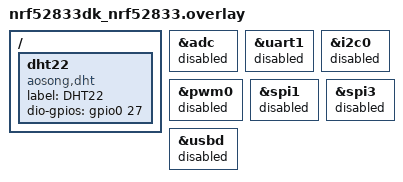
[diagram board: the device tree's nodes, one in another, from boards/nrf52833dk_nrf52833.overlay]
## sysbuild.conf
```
#
# Copyright (c) 2025 Nordic Semiconductor
#
# SPDX-License-Identifier: LicenseRef-Nordic-5-Clause
#

SB_CONFIG_MATTER=y

SB_CONFIG_MATTER_FACTORY_DATA_GENERATE=y
SB_CONFIG_MATTER_FACTORY_DATA_MERGE_WITH_FIRMWARE=y
```

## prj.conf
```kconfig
#
# Copyright (c) 2025 Nordic Semiconductor ASA
#
# SPDX-License-Identifier: LicenseRef-Nordic-5-Clause
#

#CONFIG_CHIP_DEVICE_ENABLE_KEY="10112233445566778899AABBCCDDEEFF"
#CONFIG_CHIP_DEVICE_SERIAL_NUMBER="10112233445566778899FAFBFCFDFEFA"
CONFIG_CHIP_DEVICE_DISCRIMINATOR=1113
CONFIG_CHIP_FACTORY_DATA_USE_DEFAULT_CERTS=n
CONFIG_CHIP_FACTORY_DATA_MERGE_WITH_FIRMWARE=y
CONFIG_CHIP_DEVICE_SPAKE2_PASSCODE=20202023
CONFIG_CHIP_DEVICE_SERIAL_NUMBER="12123434565678789093"

# Enable CHIP
CONFIG_CHIP=y
CONFIG_CHIP_ROTATING_DEVICE_ID=y
CONFIG_CHIP_DEVICE_GENERATE_ROTATING_DEVICE_UID=y
CONFIG_CHIP_PROJECT_CONFIG="src/chip_project_config.h"
CONFIG_CHIP_DEVICE_PRODUCT_NAME="Stube Temperatur Sensor"
CONFIG_BT_DEVICE_NAME="SchlafzimmerTemp"

# Configure ZAP file name
CONFIG_NCS_SAMPLE_MATTER_ZAP_FILE_PATH="${APPLICATION_CONFIG_DIR}/src/default_zap/temperature_sensor.zap"

# Based on https://github.com/project-chip/connectedhomeip/blob/482e6fd03196a6de45465a90003947ef4b86e0b1/docs/examples/discussion/PID_allocation_for_example_apps.md)
CONFIG_CHIP_DEVICE_PRODUCT_ID=32781
CONFIG_STD_CPP17=y

# Enable Matter pairing automatically on application start.
CONFIG_CHIP_ENABLE_PAIRING_AUTOSTART=y

# Enable Matter extended announcement and increase duration to 1 hour.
CONFIG_CHIP_BLE_EXT_ADVERTISING=y
CONFIG_CHIP_BLE_ADVERTISING_DURATION=60

# Add support for LEDs and buttons on Nordic development kits
CONFIG_DK_LIBRARY=y
CONFIG_NCS_SAMPLE_MATTER_LEDS=n

# Try to disable unused RAM blocks to reduce power consumption
CONFIG_RAM_POWER_DOWN_LIBRARY=n

# Bluetooth Low Energy configuration
CONFIG_BT_DEVICE_NAME="MatterTemperature"
CONFIG_BT_DEVICE_NAME_MAX=18

# Suspend devices when the CPU goes into sleep
CONFIG_PM_DEVICE=n
CONFIG_PM=n

# Enable system reset on fatal error
CONFIG_RESET_ON_FATAL_ERROR=y

# Disable all debug features
CONFIG_USE_SEGGER_RTT=n
CONFIG_SHELL=y
CONFIG_OPENTHREAD_SHELL=y
CONFIG_CONSOLE=y
CONFIG_UART_CONSOLE=y
CONFIG_SERIAL=y
CONFIG_LOG=y
CONFIG_LOG_MODE_MINIMAL=n
CONFIG_ASSERT_VERBOSE=n
CONFIG_ASSERT_NO_FILE_INFO=y
CONFIG_PRINTK=y
CONFIG_PRINTK_SYNC=n
CONFIG_THREAD_NAME=n
CONFIG_BOOT_BANNER=y

CONFIG_MCUMGR_TRANSPORT_UART=y

# Enable Factory Data feature
CONFIG_CHIP_FACTORY_DATA=y
CONFIG_CHIP_FACTORY_DATA_BUILD=y

# Enable Watchdog
CONFIG_NCS_SAMPLE_MATTER_WATCHDOG=y

# Enable LTO to decrease the flash usage.
CONFIG_LTO=y
CONFIG_ISR_TABLES_LOCAL_DECLARATION=y

CONFIG_NRFX_TEMP=n

CONFIG_SENSOR=y
CONFIG_DHT=y
CONFIG_DHT_LOCK_IRQS=y

CONFIG_SENSOR=y
CONFIG_TEMP_NRF5=y
```

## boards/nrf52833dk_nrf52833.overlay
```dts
/*
 * Copyright (c) 2025 Nordic Semiconductor ASA
 *
 * SPDX-License-Identifier: LicenseRef-Nordic-5-Clause
 */

/// {
//	chosen {
//		nordic,pm-ext-flash = &mx25r64;
//	};
//};

/* Disable unused peripherals to reduce power consumption */
&adc {
	status = "disabled";
};

&uart1 {
	status = "disabled";
};

&i2c0 {
	status = "disabled";
};

&pwm0 {
	status = "disabled";
};

&spi1 {
	status = "disabled";
};

&spi3 {
	status = "disabled";
};

&usbd {
	status = "disabled";
};

/ {
    dht22: dht22 {
        compatible = "aosong,dht";
        label = "DHT22";
        dio-gpios = <&gpio0 27 (GPIO_ACTIVE_HIGH)>;
    };
};
```

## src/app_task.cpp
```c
/*
 * Copyright (c) 2025 Nordic Semiconductor ASA
 *
 * SPDX-License-Identifier: LicenseRef-Nordic-5-Clause
 */

#include "app_task.h"

#include "app/matter_init.h"
#include "app/task_executor.h"
#include "board/board.h"
#include "clusters/identify.h"
#include "lib/core/CHIPError.h"
#include <drivers/include/nrfx_temp.h>

#include <app-common/zap-generated/attributes/Accessors.h>

#include <zephyr/logging/log.h>

#include <zephyr/device.h>
#include <zephyr/drivers/sensor.h>

const struct device *dht = DEVICE_DT_GET_ANY(aosong_dht);

#ifdef CONFIG_BME680
#include <zephyr/drivers/sensor.h>

const device *sBme688SensorDev = DEVICE_DT_GET_ONE(bosch_bme680);
#endif

LOG_MODULE_DECLARE(app, CONFIG_CHIP_APP_LOG_LEVEL);

using namespace ::chip;
using namespace ::chip::app;
using namespace ::chip::DeviceLayer;

namespace
{
constexpr chip::EndpointId kTemperatureSensorEndpointId = 1;

Nrf::Matter::IdentifyCluster sIdentifyCluster(kTemperatureSensorEndpointId);

#ifdef CONFIG_CHIP_ICD_UAT_SUPPORT
#ifdef CONFIG_NCS_SAMPLE_MATTER_USE_DEFAULT_BUTTON_HANDLER
#define UAT_BUTTON_MASK DK_BTN3_MSK
#endif
#endif

#ifndef CONFIG_NCS_SAMPLE_MATTER_USE_DEFAULT_BUTTON_HANDLER
constexpr int kSoftwareUpdateTimeout = 1500;
constexpr int kUatTimeout = 1500;
constexpr int kFactoryResetTimeout = 3000;
constexpr int kUatBlinkPeriod = 200;
ButtonState sBtnState = ButtonState::None;
k_timer sBtn1Timer;
#endif

} /* namespace */

void HandleUAT()
{
#ifdef CONFIG_CHIP_ICD_UAT_SUPPORT
	LOG_INF("ICD UserActiveMode has been triggered.");
	Server::GetInstance().GetICDManager().OnNetworkActivity();
#endif
}
/* nRF54T15 TAG has only a single button,
 * therefore the default handler for factory data and software update had to be overriden.
 * On other DK's only UAT is handled by the application.
 */
void AppTask::ButtonEventHandler(Nrf::ButtonState state, Nrf::ButtonMask hasChanged)
{
#ifdef CONFIG_NCS_SAMPLE_MATTER_USE_DEFAULT_BUTTON_HANDLER
	if (UAT_BUTTON_MASK & state & hasChanged) {
		HandleUAT();
	}
#else
	if (DK_BTN1_MSK & hasChanged) {
		if (DK_BTN1_MSK & state) {
			LOG_INF("Release the button within %ums to trigger Software Update", kSoftwareUpdateTimeout);
			k_timer_start(&sBtn1Timer, K_MSEC(kSoftwareUpdateTimeout), K_NO_WAIT);
			sBtnState = ButtonState::SoftwareUpdate;
		} else {
			if (sBtnState == ButtonState::SoftwareUpdate) {
#ifndef CONFIG_NCS_SAMPLE_MATTER_CUSTOM_BLUETOOTH_ADVERTISING
				if (Nrf::GetBoard().GetDeviceState() == Nrf::DeviceState::DeviceProvisioned) {
/* In this case we need to run only Bluetooth LE SMP advertising if it is available */
#ifdef CONFIG_MCUMGR_TRANSPORT_BT
					GetDFUOverSMP().StartServer();
#else
					LOG_INF("Software update is disabled");
#endif
				} else {
					/* In this case we start both Bluetooth LE SMP and Matter advertising at the
					 * same time */
					Nrf::GetBoard().StartBLEAdvertisement();
				}
#endif
			} else if (sBtnState == ButtonState::UAT) {
				HandleUAT();
			}
			/* Restore LED's state and cancel the timer */
			k_timer_stop(&sBtn1Timer);
			sBtnState = ButtonState::None;
			Nrf::GetBoard().RestoreAllLedsState();
			Nrf::GetBoard().RunLedStateHandler();
		}
	}
#endif
}
#ifndef CONFIG_NCS_SAMPLE_MATTER_USE_DEFAULT_BUTTON_HANDLER
void ButtonTimerEventHandler()
{
	if (sBtnState == ButtonState::SoftwareUpdate) {
		LOG_INF("Release the button within %ums to trigger UAT", kUatTimeout);
		k_timer_start(&sBtn1Timer, K_MSEC(kUatTimeout), K_NO_WAIT);
		sBtnState = ButtonState::UAT;

		/* Turn off all LEDs before starting blink to make sure blink is coordinated. */
		Nrf::GetBoard().ResetAllLeds();
		Nrf::GetBoard().ForEachLED([](Nrf::LEDWidget &led) { led.Blink(kUatBlinkPeriod); });
	} else if (sBtnState == ButtonState::UAT) {
		LOG_INF("Factory reset has been triggered. Release button within %ums to cancel.",
			kFactoryResetTimeout);

		/* Start timer for sFactoryResetTimeout to allow user to cancel, if required. */
		k_timer_start(&sBtn1Timer, K_MSEC(kFactoryResetTimeout), K_NO_WAIT);
		sBtnState = ButtonState::None;

		Nrf::GetBoard().ForEachLED([](Nrf::LEDWidget &led) { led.Blink(Nrf::LedConsts::kBlinkRate_ms); });
		/* If we reached here, the button was held past FactoryResetTriggerTimeout, initiate factory reset */
	} else if (sBtnState == ButtonState::None) {
		/* Actually trigger Factory Reset */
		chip::Server::GetInstance().ScheduleFactoryReset();
	}
}

void ButtonTimerTimeoutCallback(k_timer *timer)
{
	Nrf::PostTask([] { ButtonTimerEventHandler(); });
}

#endif

void AppTask::UpdateTemperatureMeasurement()
{
#ifdef CONFIG_BME680
	/* Real data from the onboard sensor*/
	int result = sensor_sample_fetch(sBme688SensorDev);
	if (result == 0) {
		sensor_value temperature;
		int result = sensor_channel_get(sBme688SensorDev, SENSOR_CHAN_AMBIENT_TEMP, &temperature);
		if (result == 0) {
			/* Defined by cluster temperature measured value = 100 x temperature in degC with resolution of
			 * 0.01 degC. val1 is an integer part of the value and val2 is fractional part in one-millionth
			 * parts. To achieve resolution of 0.01 degC val2 needs to be divided by 10000. */
			mCurrentTemperature = static_cast<int16_t>(temperature.val1 * 100 + temperature.val2 / 10000);
			LOG_DBG("New temperature measurement %d.%d *C", temperature.val1, temperature.val2);
		} else {
			LOG_ERR("Getting temperature measurement data from BME688 failed with: %d", result);
		}
	} else {
		LOG_ERR("Fetching data from BME688 sensor failed with: %d", result);
	}
#else
	 //mCurrentTemperature = (int16_t) nrfx_temp_calculate(nrfx_temp_result_get()) + 150;
	 //nrfx_temp_measure();

        struct sensor_value temp, hum;

        int ret = sensor_sample_fetch(dht);
	if(ret != 0)
	{
		//LOG_ERR("Error reading sensor %d", ret);
		return;
	}
	ret = sensor_channel_get(dht, SENSOR_CHAN_AMBIENT_TEMP, &temp);
	if(ret != 0)
	{
		LOG_ERR("Error translating temperature %d", ret);
		return;
	}
        ret = sensor_channel_get(dht, SENSOR_CHAN_HUMIDITY, &hum);
	if(ret != 0)
	{
		LOG_ERR("Error translating humidity %d", ret);
		return;
	}

	mCurrentTemperature = (int16_t)(temp.val1 * 100 + temp.val2 / 10000);
	mCurrentHumidity = (int16_t)(hum.val1 * 100 + hum.val2 / 10000);
	//LOG_INF("TEMP 1: %u", temp.val1);
	//LOG_INF("TEMP 2: %u", temp.val2);
	//LOG_INF("HUM 1: %u", hum.val1);
	//LOG_INF("HUM 2: %u", hum.val2);
	//LOG_INF("Temp: %d.%06d C\n", temp.val1, temp.val2);
	//LOG_INF("Humidity: %d.%06d %%\n", hum.val1, hum.val2);
#endif
}

void AppTask::UpdateTemperatureTimeoutCallback(k_timer *timer)
{
	if (!timer || !timer->user_data) {
		return;
	}

	DeviceLayer::PlatformMgr().ScheduleWork(
		[](intptr_t p) {
			AppTask::Instance().UpdateTemperatureMeasurement();

			Protocols::InteractionModel::Status status =
				Clusters::TemperatureMeasurement::Attributes::MeasuredValue::Set(
					kTemperatureSensorEndpointId, AppTask::Instance().GetCurrentTemperature());

			if (status != Protocols::InteractionModel::Status::Success) {
				LOG_ERR("Updating temperature measurement failed %x", to_underlying(status));
			}

			status =
				Clusters::RelativeHumidityMeasurement::Attributes::MeasuredValue::Set(
					kTemperatureSensorEndpointId, AppTask::Instance().GetCurrentHumidity());

			if (status != Protocols::InteractionModel::Status::Success) {
				LOG_ERR("Updating humidity measurement failed %x", to_underlying(status));
			}
		},
		reinterpret_cast<intptr_t>(timer->user_data));
}

CHIP_ERROR AppTask::Init()
{
	/* Initialize Matter stack */
	ReturnErrorOnFailure(Nrf::Matter::PrepareServer());

	if (!Nrf::GetBoard().Init(ButtonEventHandler)) {
		LOG_ERR("User interface initialization failed.");
		return CHIP_ERROR_INCORRECT_STATE;
	}

	/* Register Matter event handler that controls the connectivity status LED based on the captured Matter network
	 * state. */
	ReturnErrorOnFailure(Nrf::Matter::RegisterEventHandler(Nrf::Board::DefaultMatterEventHandler, 0));
#ifdef CONFIG_BME680
	if (!device_is_ready(sBme688SensorDev)) {
		LOG_ERR("BME688 sensor device not ready");
		return chip::System::MapErrorZephyr(-ENODEV);
	}
#endif

	ReturnErrorOnFailure(sIdentifyCluster.Init());

	return Nrf::Matter::StartServer();
}

CHIP_ERROR AppTask::StartApp()
{
	//const nrfx_temp_config_t temp_config = NRFX_TEMP_DEFAULT_CONFIG;
	//nrfx_temp_init(&temp_config, NULL);
	//nrfx_temp_measure();


	if (!device_is_ready(dht)) {
		LOG_ERR("DHT device not ready\n");
		return CHIP_ERROR_INCORRECT_STATE;
	}

	ReturnErrorOnFailure(Init());

	DataModel::Nullable<int16_t> val;
	Protocols::InteractionModel::Status status =
		Clusters::TemperatureMeasurement::Attributes::MinMeasuredValue::Get(kTemperatureSensorEndpointId, val);

	if (status != Protocols::InteractionModel::Status::Success || val.IsNull()) {
		LOG_ERR("Failed to get temperature measurement min value %x", to_underlying(status));
		return CHIP_ERROR_INCORRECT_STATE;
	}

	mTemperatureSensorMinValue = val.Value();

	status = Clusters::TemperatureMeasurement::Attributes::MaxMeasuredValue::Get(kTemperatureSensorEndpointId, val);

	if (status != Protocols::InteractionModel::Status::Success || val.IsNull()) {
		LOG_ERR("Failed to get temperature measurement max value %x", to_underlying(status));
		return CHIP_ERROR_INCORRECT_STATE;
	}

	mTemperatureSensorMaxValue = val.Value();

	k_timer_init(&mTimer, AppTask::UpdateTemperatureTimeoutCallback, nullptr);
	k_timer_user_data_set(&mTimer, this);
	k_timer_start(&mTimer, K_MSEC(kTemperatureMeasurementIntervalMs), K_MSEC(kTemperatureMeasurementIntervalMs));
#ifndef CONFIG_NCS_SAMPLE_MATTER_USE_DEFAULT_BUTTON_HANDLER
	k_timer_init(&sBtn1Timer, &ButtonTimerTimeoutCallback, nullptr);
#endif
	while (true) {
		Nrf::DispatchNextTask();
	}

	return CHIP_NO_ERROR;
}
```

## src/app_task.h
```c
/*
 * Copyright (c) 2025 Nordic Semiconductor ASA
 *
 * SPDX-License-Identifier: LicenseRef-Nordic-5-Clause
 */

#pragma once

#include "board/board.h"

#include <platform/CHIPDeviceLayer.h>

struct Identify;

#ifndef CONFIG_NCS_SAMPLE_MATTER_USE_DEFAULT_BUTTON_HANDLER
enum class ButtonState { None, SoftwareUpdate, UAT };
#endif

class AppTask {
public:
	static AppTask &Instance()
	{
		static AppTask sAppTask;
		return sAppTask;
	};

	CHIP_ERROR StartApp();

	/* Defined by cluster temperature measured value = 100 x temperature in degC with resolution of
	 * 0.01 degC. */
	void UpdateTemperatureMeasurement();

	int16_t GetCurrentTemperature() const { return mCurrentTemperature; }
	int16_t GetCurrentHumidity() const { return mCurrentHumidity; }

private:
	CHIP_ERROR Init();
	k_timer mTimer;

	static constexpr uint16_t kTemperatureMeasurementIntervalMs = 10 * 1000; /* 10 seconds */
	static constexpr uint16_t kTemperatureMeasurementStep = 100; /* 1 degree Celsius */

	static void UpdateTemperatureTimeoutCallback(k_timer *timer);

	static void ButtonEventHandler(Nrf::ButtonState state, Nrf::ButtonMask hasChanged);

	int16_t mTemperatureSensorMaxValue = 0;
	int16_t mTemperatureSensorMinValue = 0;
	int16_t mCurrentTemperature = 0;
	int16_t mCurrentHumidity = 0;
};
```

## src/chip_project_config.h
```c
/*
 * Copyright (c) 2025 Nordic Semiconductor ASA
 *
 * SPDX-License-Identifier: LicenseRef-Nordic-5-Clause
 */

/**
 *    @file
 *          Example project configuration file for CHIP.
 *
 *          This is a place to put application or project-specific overrides
 *          to the default configuration values for general CHIP features.
 *
 */

#pragma once

#define CHIP_DEVICE_CONFIG_NAME "SchlafzimmerTemperatur"
```
